# RE01_1500KB register map
Vendor: Renesas Electronics Corporation; Series: RE01_1500KB; File version: 1.20
CPU: CM0PLUS r0p1, little endian, MPU, no FPU, VTOR, 2 interrupt priority bits
Registers are 8-bit, read-write, reset 0x0 unless marked. A register's access mark holds for its fields unless they carry their own. Offsets are from the block's base; [hi:lo] are bit positions; lines under a group give offsets from that group; {n}, {i} and the like mark numbered series; 'fields as' and 'values as' point back to an identical list.

## R12DA — 12-bit D/A converter
Base 0x4005E000
0x00 DADR0 16-bit — D/A Data Register 0
  [15:0] DADR0 — D/A Data RegisterNOTE: When DADPR.DPSEL = 0, the high-order 4 bits are fixed to 0: right justified format. When DADPR.DPSEL = 1, the low-order 4 bits are fixed to 0: left justified format.
0x04 DACR reset 0x1F — D/A Control Register
  [6] DAOE0 — D/A Output Enable 0
    0=Analog output of channel 0 (DA0) is disabled; 1=D/A conversion of channel 0 is enabled. Analog output of channel 0 (DA0) is enabled.
0x05 DADPR — DADR0 Format Select Register
  [7] DPSEL — DADRm Format Select
    0=Right justified format; 1=Left justified format
0x08 DAAMPCR
  [6] DAAMP0

## SMPU — Bus Slave MPU
Base 0x40000C00
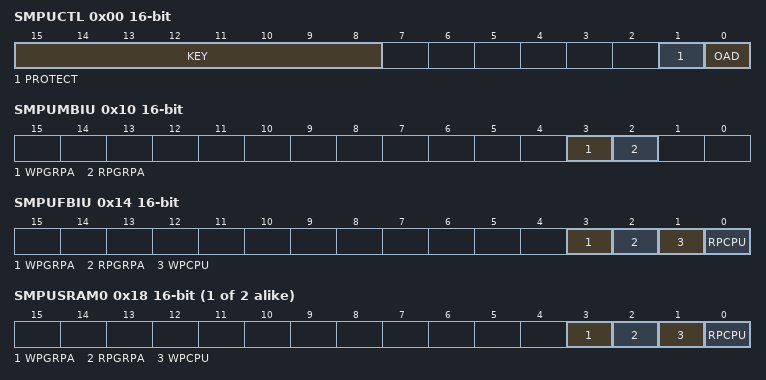
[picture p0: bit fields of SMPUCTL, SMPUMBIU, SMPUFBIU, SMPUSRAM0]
0x00 SMPUCTL 16-bit — Slave MPU Control Register
  [15:8] KEY — Key Code This bit is used to enable or disable writing of the PROTECT and OAD bit.The data written to these bits are not stored.
    165=Writing to the PROTECT and OAD bit is valid, when the KEY bits are written 0xA5; other=others (Writing to the PROTECT and OAD bit is invalid.)
  [1] PROTECT — Protection of register
    0=All Bus Slave register writing is possible; 1=All Bus Slave register writing is protected. Read is possible.
  [0] OAD — Operation after detection
    0=Non-maskable interrupt; 1=Reset
0x10 SMPUMBIU 16-bit — Access Control Register for MBIU
  [3] WPGRPA — Master Group A Write protection
    0=Master group A write of memory protection is disabled; 1=Master group A write of memory protection is enabled
  [2] RPGRPA — Master Group A Read protection
    0=Master group A read of memory protection is disabled; 1=Master group A read of memory protection is enabled
0x14 SMPUFBIU 16-bit — Access Control Register for FBIU
  [3] WPGRPA — Master Group A Write protection
    values as SMPUMBIU.WPGRPA
  [2] RPGRPA — Master Group A Read protection
    values as SMPUMBIU.RPGRPA
  [1] WPCPU — CPU Write protection
    0=CPU write of memory protection is disabled; 1=CPU write of memory protection is enabled
  [0] RPCPU — CPU Read protection
    0=CPU read of memory protection is disabled; 1=CPU read of memory protection is enabled
{0x18+4i} SMPUSRAM{i} (i=0..1) 16-bit — Access Control Register for SRAM{i}
  fields as SMPUFBIU
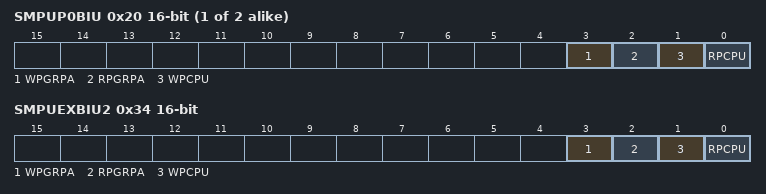
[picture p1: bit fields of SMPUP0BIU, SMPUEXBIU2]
0x20 SMPUP{x}BIU (x=0,2; step 0x4) 16-bit — Access Control Register for P{x}BIU
  fields as SMPUFBIU
0x34 SMPUEXBIU2 16-bit — Access Control Register for EXBIU2
  fields as SMPUFBIU

## SPMON — CPU Stack Pointer Monitor
Base 0x40000D00
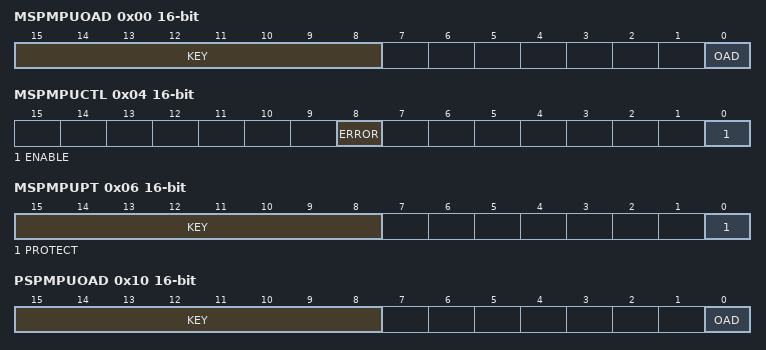
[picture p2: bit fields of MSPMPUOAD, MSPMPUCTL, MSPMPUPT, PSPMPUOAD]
0x00 MSPMPUOAD 16-bit — Stack Pointer Monitor Operation After Detection Register
  [15:8] KEY — Write Keyword The data written to these bits are not stored.
    165=Writing to the OAD bit is valid, when the KEY bits are written 0xA5; other=others (Writing to the OAD bit is invalid.)
  [0] OAD — Operation after detection
    1=Internal reset; 0=Non-maskable interrupt
0x04 MSPMPUCTL 16-bit (reset mask 0xFEFF) — Stack Pointer Monitor Access Control Register
  [8] ERROR — SP_main monitor error flag
    0=SP_main has not overflowed or underflowed; 1=SP_main has overflowed or underflowed
  [0] ENABLE — SP_main monitor enable
    0=SP_main monitor is disabled; 1=SP_main monitor is enabled
0x06 MSPMPUPT 16-bit — Stack Pointer Monitor Protection Register
  [15:8] KEY — Write Keyword The data written to these bits are not stored.
    165=Writing to the PROTECT bit is valid, when the KEY bits are written 0xA5; other=others (Writing to the PROTECT bit is invalid.)
  [0] PROTECT — Protection of register (MSPMPUCTL, MSPMPUSA and MSPMPUEA)
    0=Stack Pointer Monitor register writing is possible; 1=Stack Pointer Monitor register writing is protected
0x08 MSPMPUSA 32-bit (reset mask 0x3) — Main Stack Pointer Monitor Start Address Register
  [31:0] MSPMPUSA — Region start address resister
0x0C MSPMPUEA 32-bit reset 0x3 (reset mask 0x3) — Main Stack Pointer Monitor End Address Register
  [31:0] MSPMPUEA — Region end address resister
0x10 PSPMPUOAD 16-bit — Stack Pointer Monitor Operation After Detection Register
  fields as MSPMPUOAD
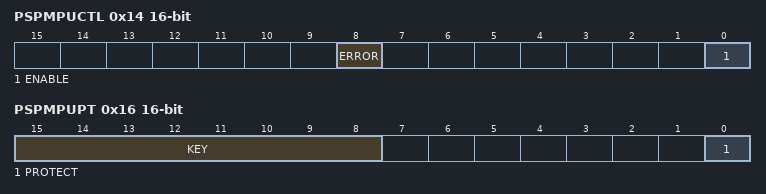
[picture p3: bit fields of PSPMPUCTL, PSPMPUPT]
0x14 PSPMPUCTL 16-bit (reset mask 0xFEFF) — Stack Pointer Monitor Access Control Register
  [8] ERROR — SP_process monitor error flag
    0=SP_process has not overflowed or underflowed; 1=SP_process has overflowed or underflowed
  [0] ENABLE — SP_process monitor enable
    0=SP_process monitor is disabled; 1=SP_process monitor is enabled
0x16 PSPMPUPT 16-bit — Stack Pointer Monitor Protection Register
  fields as MSPMPUPT
0x18 PSPMPUSA 32-bit (reset mask 0x3) — Process Stack Pointer Monitor Start Address Register
  [31:0] PSPMPUSA — Region start address resister
0x1C PSPMPUEA 32-bit reset 0x3 (reset mask 0x3) — Process Stack Pointer Monitor End Address Register
  [31:0] PSPMPUEA — Region end address resister

## TEMPS — Temperature Sensor
Base 0x01008000; alternate view of FLASH
0x17C TSCDR 32-bit ro (reset mask 0xFFFF0000) — Temperature Sensor Control Register
  [15:0] TSCDR
0x3F055000 TSCR — Temperature Sensor Control Register
  [7] TSEN

## TMR0
Base 0x40052000; alternate view of TMR1,TMR01
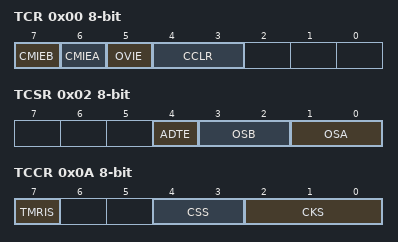
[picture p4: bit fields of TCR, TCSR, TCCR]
0x00 TCR
  [7] CMIEB
  [6] CMIEA
  [5] OVIE
  [4:3] CCLR
    0=00; 1=01; 2=10; 3=11
0x02 TCSR
  [4] ADTE
  [3:2] OSB
    0=00; 1=01; 2=10; 3=11
  [1:0] OSA
    0=00; 1=01; 2=10; 3=11
0x04 TCORA reset 0xFF
0x06 TCORB reset 0xFF
0x08 TCNT
0x0A TCCR
  [7] TMRIS
  [4:3] CSS
    0=00; 1=01; 2=10; 3=11
  [2:0] CKS
    0=000; 1=001; 2=010; 3=011; 4=100; 5=101; 6=110; 7=111

## TMR01
Base 0x40052000; alternate view of TMR0
0x04 TCORA 16-bit reset 0xFFFF
0x06 TCORB 16-bit reset 0xFFFF
0x08 TCNT 16-bit

## TMR1
Base 0x40052000; alternate view of TMR0
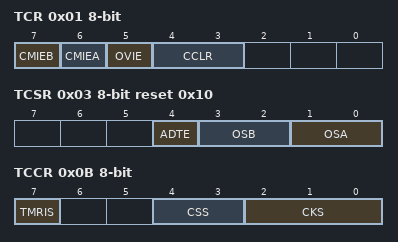
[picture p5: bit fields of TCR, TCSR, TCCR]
0x01 TCR
  [7] CMIEB
  [6] CMIEA
  [5] OVIE
  [4:3] CCLR
    0=00; 1=01; 2=10; 3=11
0x03 TCSR reset 0x10
  [4] ADTE
  [3:2] OSB
    0=00; 1=01; 2=10; 3=11
  [1:0] OSA
    0=00; 1=01; 2=10; 3=11
0x05 TCORA reset 0xFF
0x07 TCORB reset 0xFF
0x09 TCNT
0x0B TCCR
  [7] TMRIS
  [4:3] CSS
    0=00; 1=01; 2=10; 3=11
  [2:0] CKS
    0=000; 1=001; 2=010; 3=011; 4=100; 5=101; 6=110; 7=111

## VREF
Base 0x40086A80
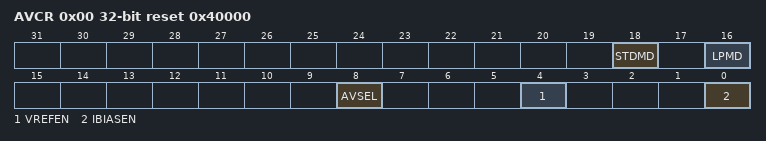
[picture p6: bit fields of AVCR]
0x00 AVCR 32-bit reset 0x40000
  [18] STDMD, [16] LPMD, [8] AVSEL, [4] VREFEN, [0] IBIASEN

## WDT — Watchdog Timer
Base 0x40044200
0x00 WDTRR reset 0xFF — WDT Refresh Register
  [7:0] WDTRR — WDTRR is an 8-bit register that refreshes the down-counter of the WDT.
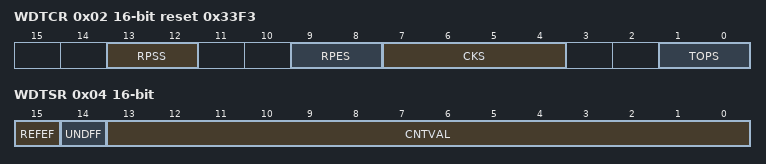
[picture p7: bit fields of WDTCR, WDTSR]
0x02 WDTCR 16-bit reset 0x33F3 — WDT Control Register
  [13:12] RPSS — Window Start Position Selection
    0=25 percent; 1=50 percent; 2=75 percent; 3=100 percent (window start position is not specified)
  [9:8] RPES — Window End Position Selection
    0=75 percent; 1=50 percent; 2=25 percent; 3=0 percent (window end position is not specified)
  [7:4] CKS — Clock Division Ratio Selection
    1=PCLK/4; 4=PCLK/64; 15=PCLK/128; 6=PCLK/512; 7=PCLK/2048; 8=PCLK/8192; other=others (setting prohibited)
  [1:0] TOPS — Timeout Period Selection
    0=1,024 cycles (03FFh); 1=4,096 cycles (0FFFh); 2=8,192 cycles (1FFFh); 3=16,384 cycles (3FFFh)
0x04 WDTSR 16-bit — WDT Status Register
  [15] REFEF — Refresh Error Flag
    0=No refresh error occurred; 1=Refresh error occurred
  [14] UNDFF — Underflow Flag
    0=No underflow occurred; 1=Underflow occurred
  [13:0] CNTVAL ro — Down-Counter ValueValue counted by the down-counter
0x06 WDTRCR reset 0x80 — WDT Reset Control Register
  [7] RSTIRQS — Reset Interrupt Request Selection
    0=Non-maskable interrupt request or interrupt request output is enabled; 1=Reset output is enabled
0x08 WDTCSTPR reset 0x80
  [7] SLCSTP — Sleep-Mode Count Stop Control
    0=Count stop is disabled; 1=Count is stopped at a transition to sleep mode
